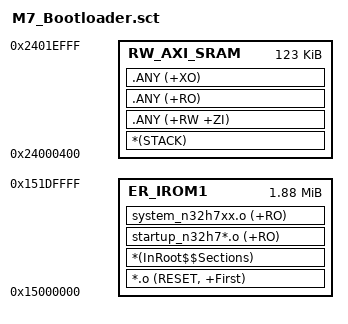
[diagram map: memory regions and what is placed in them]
; *************************************************************
; *** Scatter-Loading Description File generated by uVision ***
; *************************************************************

LR_IROM1 0x15000000 0x001E0000  {    ; load region size_region
  ER_IROM1 0x15000000 0x001E0000  {  ; load address = execution address
   *.o (RESET, +First)
   *(InRoot$$Sections)
   startup_n32h7*.o (+RO)
   system_n32h7xx.o (+RO)
  }
  
  RW_AXI_SRAM 0x24000400 0x0001EC00  {  ; 124K AXI-SRAM stack, top 4KB (0x2401F000~0x2401FFFF) reserved for OTA flag
   *(STACK)
   .ANY (+RW +ZI) 
   .ANY (+RO)
   .ANY (+XO)   
  }  
  
}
